VERSION "HIPBNYYYYYYYYYYYYYYYYYYYYYYYYYYYYYYYYYYYYY/4/%%%/4/'%**4YYY///"

NS_ :

BS_:

BU_: Aceinna

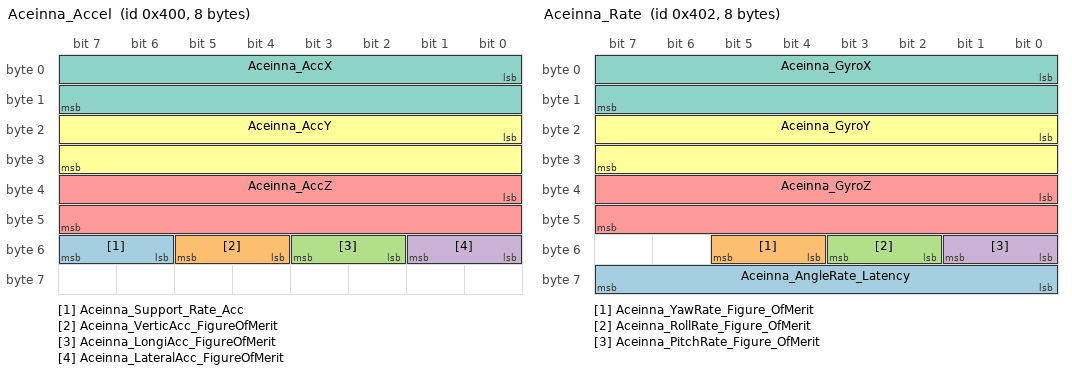
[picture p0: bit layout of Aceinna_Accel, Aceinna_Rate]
BO_ 1024 Aceinna_Accel: 8 Aceinna
 SG_ Aceinna_Support_Rate_Acc : 54|2@1+ (1,0) [0|0] "" Vector__XXX
 SG_ Aceinna_VerticAcc_FigureOfMerit : 52|2@1+ (1,0) [0|0] "" Vector__XXX
 SG_ Aceinna_LongiAcc_FigureOfMerit : 50|2@1+ (1,0) [0|0] "" Vector__XXX
 SG_ Aceinna_LateralAcc_FigureOfMerit : 48|2@1+ (1,0) [0|0] "" Vector__XXX
 SG_ Aceinna_AccZ : 32|16@1+ (0.01,-320) [-320|335.35] "m/s2" Vector__XXX
 SG_ Aceinna_AccY : 16|16@1+ (0.01,-320) [-320|335.35] "m/s2" Vector__XXX
 SG_ Aceinna_AccX : 0|16@1+ (0.01,-320) [-320|335.35] "m/s2" Vector__XXX

BO_ 1025 GPS_Speed: 8 Aceinna
 SG_ Speed : 0|16@1- (0.001,0) [-1000|1000] "kph" Vector__XXX

BO_ 1026 Aceinna_Rate: 8 Aceinna
 SG_ Aceinna_AngleRate_Latency : 56|8@1+ (0.5,0) [0|0] "ms" Vector__XXX
 SG_ Aceinna_YawRate_Figure_OfMerit : 52|2@1+ (1,0) [0|0] "" Vector__XXX
 SG_ Aceinna_RollRate_Figure_OfMerit : 50|2@1+ (1,0) [0|0] "" Vector__XXX
 SG_ Aceinna_PitchRate_Figure_OfMerit : 48|2@1+ (1,0) [0|0] "" Vector__XXX
 SG_ Aceinna_GyroZ : 32|16@1+ (0.0078125,-250) [-250|261.9921875] "deg/s" Vector__XXX
 SG_ Aceinna_GyroY : 16|16@1+ (0.0078125,-250) [-250|261.9921875] "deg/s" Vector__XXX
 SG_ Aceinna_GyroX : 0|16@1+ (0.0078125,-250) [-250|261.9921875] "deg/s" Vector__XXX
